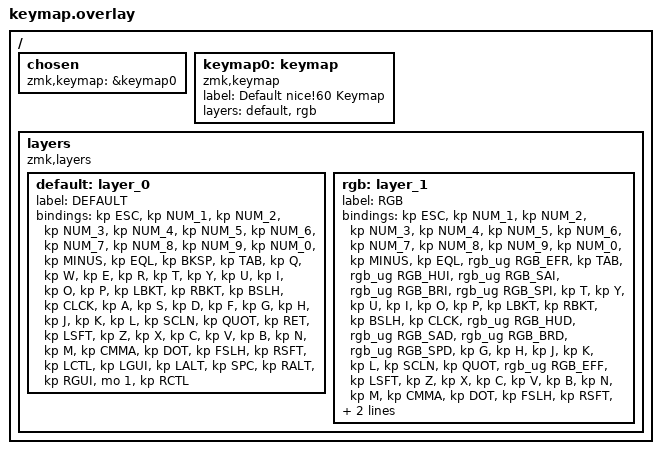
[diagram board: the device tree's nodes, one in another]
#include <behaviors.dtsi>
#include <dt-bindings/zmk/keys.h>
#include <dt-bindings/zmk/matrix-transform.h>
#include <dt-bindings/zmk/rgb.h>

/ {
	chosen {
		zmk,keymap = &keymap0;
	};
	
	keymap0: keymap {
		compatible = "zmk,keymap";
		label ="Default nice!60 Keymap";
		layers = <&default &rgb>;
	};

	layers {
		compatible = "zmk,layers";

		default: layer_0 {
			label = "DEFAULT";
// ------------------------------------------------------------------------------------------
// | ESC |  1  |  2  |  3  |  4  |  5  |  6  |  7  |  8  |  9  |  0  |  -  |  =  |   BKSP   |
// | TAB  |  Q  |  W  |  E  |  R  |  T  |  Y  |  U  |  I  |  O  |  P  |  [  |  ]  |   "|"   |
// | CAPS  |  A  |  S  |  D  |  F  |  G  |  H  |  J  |  K  |  L  |  ;  |  '  |     ENTER    |
// |  SHIFT  |  Z  |  X  |  C  |  V  |  B  |  N  |  M  |  ,  |  .  |  /  |      SHIFT       |
// |  CTL  |  WIN  |  ALT  |            SPACE              |  ALT  |  WIN  |  MO(1) |  CTL  |
// ------------------------------------------------------------------------------------------
			bindings = <
	&kp ESC &kp NUM_1 &kp NUM_2 &kp NUM_3 &kp NUM_4 &kp NUM_5 &kp NUM_6 &kp NUM_7 &kp NUM_8 &kp NUM_9 &kp NUM_0 &kp MINUS &kp EQL  &kp BKSP
	&kp TAB  &kp   Q   &kp   W   &kp   E   &kp   R   &kp   T   &kp   Y   &kp   U   &kp   I   &kp   O   &kp   P   &kp LBKT &kp RBKT &kp BSLH
	&kp CLCK  &kp   A   &kp   S   &kp   D   &kp   F   &kp   G   &kp   H   &kp   J   &kp   K   &kp   L   &kp  SCLN  &kp  QUOT        &kp RET
	&kp LSFT   &kp   Z   &kp   X   &kp   C   &kp   V   &kp   B   &kp   N   &kp   M   &kp   CMMA   &kp   DOT   &kp   FSLH           &kp RSFT
	&kp LCTL &kp   LGUI   &kp   LALT                     &kp SPC                         &kp   RALT    &kp   RGUI     &mo 1      &kp   RCTL
			>;
		};

		rgb: layer_1 {
			label = "RGB";
// ------------------------------------------------------------------------------------------
// | ESC |  1  |  2  |  3  |  4  |  5  |  6  |  7  |  8  |  9  |  0  |  -  |  =  |   BKSP   |
// | TAB  |  Q  |  W  |  E  |  R  |  T  |  Y  |  U  |  I  |  O  |  P  |  [  |  ]  |   "|"   |
// | CAPS  |  A  |  S  |  D  |  F  |  G  |  H  |  J  |  K  |  L  |  ;  |  '  |     ENTER    |
// |  SHIFT  |  Z  |  X  |  C  |  V  |  B  |  N  |  M  |  ,  |  .  |  /  |      SHIFT       |
// |  CTL  |  WIN  |  ALT  |            SPACE              |  ALT  |  WIN  |  MENU  |  CTL  |
// ------------------------------------------------------------------------------------------
			bindings = <
	&kp ESC &kp NUM_1 &kp NUM_2 &kp NUM_3 &kp NUM_4 &kp NUM_5 &kp NUM_6 &kp NUM_7 &kp NUM_8 &kp NUM_9 &kp NUM_0 &kp MINUS &kp EQL  &rgb_ug RGB_EFR
	&kp TAB  &rgb_ug RGB_HUI &rgb_ug RGB_SAI &rgb_ug RGB_BRI &rgb_ug RGB_SPI   &kp   T   &kp   Y   &kp   U   &kp   I   &kp   O   &kp   P   &kp LBKT &kp RBKT &kp BSLH
	&kp CLCK  &rgb_ug RGB_HUD &rgb_ug RGB_SAD &rgb_ug RGB_BRD &rgb_ug RGB_SPD  &kp   G   &kp   H   &kp  J   &kp   K   &kp   L   &kp  SCLN  &kp QUOT &rgb_ug RGB_EFF
	&kp LSFT   &kp   Z   &kp   X   &kp   C   &kp   V   &kp   B   &kp   N   &kp   M   &kp   CMMA   &kp   DOT   &kp   FSLH           &kp RSFT
	&kp LCTL &kp   LGUI   &kp   LALT                  &rgb_ug RGB_TOG                    &kp   RALT    &kp   RGUI     &trans     &kp   RCTL
			>;
		};
	};
};
